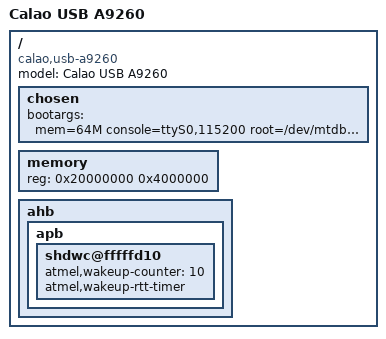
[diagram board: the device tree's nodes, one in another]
/*
 * usb_a9260.dts - Device Tree file for Caloa USB A9260 board
 *
 *  Copyright (C) 2011-2012 Jean-Christophe PLAGNIOL-VILLARD <plagnioj@jcrosoft.com>
 *
 * Licensed under GPLv2 or later.
 */
/dts-v1/;
#include "at91sam9260.dtsi"
#include "usb_a9260_common.dtsi"

/ {
	model = "Calao USB A9260";
	compatible = "calao,usb-a9260", "atmel,at91sam9260", "atmel,at91sam9";

	chosen {
		bootargs = "mem=64M console=ttyS0,115200 root=/dev/mtdblock5 rw rootfstype=ubifs";
	};

	memory {
		reg = <0x20000000 0x4000000>;
	};

	ahb {
		apb {
			shdwc@fffffd10 {
				atmel,wakeup-counter = <10>;
				atmel,wakeup-rtt-timer;
			};
		};
	};
};
